# RTC_C__Real_Time_Clock_3 register map
Vendor: Texas Instruments
Peripheral module from a debugger description file (folder msp430).
Registers are 16-bit, read-write, reset 0x0 unless marked. A register's access mark holds for its fields unless they carry their own. Offsets are as the file gives them; lines under a group give offsets from that group; [hi:lo] are bit positions; {n}, {i} and the like mark numbered series; 'fields as' and 'values as' point back to an identical list; <NAME> marks a mode.

## RTC_C_Real_Time_Clock
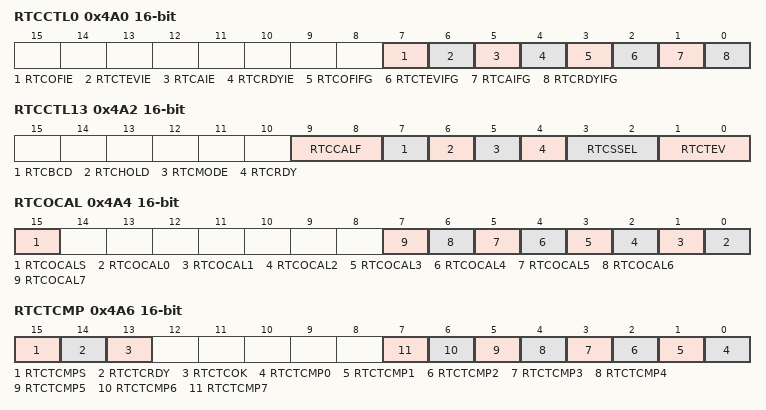
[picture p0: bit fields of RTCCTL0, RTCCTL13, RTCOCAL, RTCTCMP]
0x4A0 RTCCTL0 — Real Timer Clock Control 0/Key
  [7] RTCOFIE — RTC 32kHz cyrstal oscillator fault interrupt enable
  [6] RTCTEVIE — RTC Time Event Interrupt Enable Flag
  [5] RTCAIE — RTC Alarm Interrupt Enable Flag
  [4] RTCRDYIE — RTC Ready Interrupt Enable Flag
  [3] RTCOFIFG — RTC 32kHz cyrstal oscillator fault interrupt flag
  [2] RTCTEVIFG — RTC Time Event Interrupt Flag
  [1] RTCAIFG — RTC Alarm Interrupt Flag
  [0] RTCRDYIFG — RTC Ready Interrupt Flag
0x4A2 RTCCTL13 — Real Timer Clock Control 1/3
  [9:8] RTCCALF — RTC Calibration Frequency Bit 1
    0=RTC Calibration Frequency: No Output; 1=RTC Calibration Frequency: 512 Hz; 2=RTC Calibration Frequency: 256 Hz; 3=RTC Calibration Frequency: 1 Hz
  [7] RTCBCD — RTC BCD 0:Binary / 1:BCD
  [6] RTCHOLD
  [5] RTCMODE — RTC Mode 0:Counter / 1: Calendar
  [4] RTCRDY — RTC Ready
  [3:2] RTCSSEL — RTC Source Select 1
    0=RTC Source Select ACLK; 1=RTC Source Select SMCLK; 2=RTC Source Select RT1PS; 3=RTC Source Select RT1PS
  [1:0] RTCTEV — RTC Time Event 1
    0=RTC Time Event: 0 (Min. changed); 1=RTC Time Event: 1 (Hour changed); 2=RTC Time Event: 2 (12:00 changed); 3=RTC Time Event: 3 (00:00 changed)
0x4A4 RTCOCAL — Real Timer Clock Offset Calibartion
  [15] RTCOCALS — RTC Offset Calibration Sign
  [n] RTCOCAL{n} (n=0..7) — RTC Offset Calibration Bit {n}
0x4A6 RTCTCMP — Real Timer Temperature Compensation
  [15] RTCTCMPS — RTC Temperature Compensation Sign
  [14] RTCTCRDY — RTC Temperature compensation ready
  [13] RTCTCOK — RTC Temperature compensation write OK
  [n] RTCTCMP{n} (n=0..7) — RTC Temperature Compensation Bit {n}
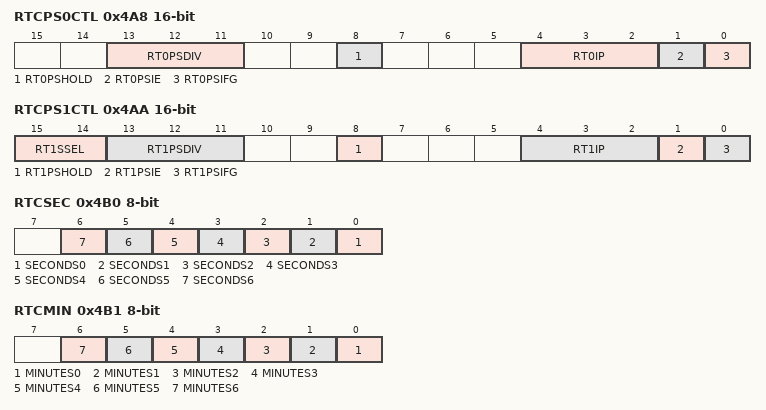
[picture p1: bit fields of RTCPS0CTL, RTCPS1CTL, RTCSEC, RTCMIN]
0x4A8 RTCPS0CTL — Real Timer Prescale Timer 0 Control
  [13:11] RT0PSDIV — RTC Prescale Timer 0 Clock Divide Bit: 2
    0=RTC Prescale Timer 0 Clock Divide: /2; 1=RTC Prescale Timer 0 Clock Divide: /4; 2=RTC Prescale Timer 0 Clock Divide: /8; 3=RTC Prescale Timer 0 Clock Divide: /16; 4=RTC Prescale Timer 0 Clock Divide: /32; 5=RTC Prescale Timer 0 Clock Divide: /64; 6=RTC Prescale Timer 0 Clock Divide: /128; 7=RTC Prescale Timer 0 Clock Divide: /256
  [8] RT0PSHOLD — RTC Prescale Timer 0 Hold
  [4:2] RT0IP — RTC Prescale Timer 0 Interrupt Interval Bit: 2
    0=RTC Prescale Timer 0 Interrupt Interval /2; 1=RTC Prescale Timer 0 Interrupt Interval /4; 2=RTC Prescale Timer 0 Interrupt Interval /8; 3=RTC Prescale Timer 0 Interrupt Interval /16; 4=RTC Prescale Timer 0 Interrupt Interval /32; 5=RTC Prescale Timer 0 Interrupt Interval /64; 6=RTC Prescale Timer 0 Interrupt Interval /128; 7=RTC Prescale Timer 0 Interrupt Interval /256
  [1] RT0PSIE — RTC Prescale Timer 0 Interrupt Enable Flag
  [0] RT0PSIFG — RTC Prescale Timer 0 Interrupt Flag
0x4AA RTCPS1CTL — Real Timer Prescale Timer 1 Control
  [15:14] RT1SSEL — RTC Prescale Timer 1 Source Select Bit: 1
    {v}=RTC Prescale Timer 1 Source Select: {v} (v=0..3)
  [13:11] RT1PSDIV — RTC Prescale Timer 1 Clock Divide Bit: 2
    0=RTC Prescale Timer 1 Clock Divide: /2; 1=RTC Prescale Timer 1 Clock Divide: /4; 2=RTC Prescale Timer 1 Clock Divide: /8; 3=RTC Prescale Timer 1 Clock Divide: /16; 4=RTC Prescale Timer 1 Clock Divide: /32; 5=RTC Prescale Timer 1 Clock Divide: /64; 6=RTC Prescale Timer 1 Clock Divide: /128; 7=RTC Prescale Timer 1 Clock Divide: /256
  [8] RT1PSHOLD — RTC Prescale Timer 1 Hold
  [4:2] RT1IP — RTC Prescale Timer 1 Interrupt Interval Bit: 2
    0=RTC Prescale Timer 1 Interrupt Interval /2; 1=RTC Prescale Timer 1 Interrupt Interval /4; 2=RTC Prescale Timer 1 Interrupt Interval /8; 3=RTC Prescale Timer 1 Interrupt Interval /16; 4=RTC Prescale Timer 1 Interrupt Interval /32; 5=RTC Prescale Timer 1 Interrupt Interval /64; 6=RTC Prescale Timer 1 Interrupt Interval /128; 7=RTC Prescale Timer 1 Interrupt Interval /256
  [1] RT1PSIE — RTC Prescale Timer 1 Interrupt Enable Flag
  [0] RT1PSIFG — RTC Prescale Timer 1 Interrupt Flag
0x4AC RTCPS access not given reset not defined — Real Timer Prescale Timer Control
0x4AE RTCIV access not given reset not defined — Real Time Clock Interrupt Vector
0x4B0 RTCTIM0 access not given reset not defined — Real Time Clock Time 0
0x4B0 RTCSEC 8-bit — Real Time Clock Seconds
  [n] SECONDS{n} (n=0..6) — Real Time Clock Seconds Bit: {n}
0x4B1 RTCMIN 8-bit — Real Time Clock Minutes
  [n] MINUTES{n} (n=0..6) — Real Time Clock Minutes Bit: {n}
0x4B2 RTCTIM1 access not given reset not defined — Real Time Clock Time 1
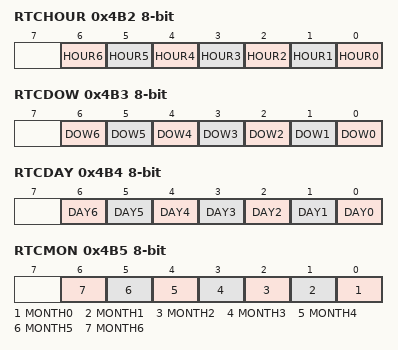
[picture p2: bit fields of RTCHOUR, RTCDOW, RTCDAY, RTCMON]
0x4B2 RTCHOUR 8-bit — Real Time Clock Hour
  [n] HOUR{n} (n=0..6) — Real Time Clock Hour Bit: {n}
0x4B3 RTCDOW 8-bit — Real Time Clock Day of week
  [n] DOW{n} (n=0..6) — Real Time Clock DOW Bit: {n}
0x4B4 RTCDATE access not given reset not defined — Real Time Clock Date
0x4B4 RTCDAY 8-bit — Real Time Clock Day
  [n] DAY{n} (n=0..6) — Real Time Clock Day Bit: {n}
0x4B5 RTCMON 8-bit — Real Time Clock Month
  [n] MONTH{n} (n=0..6) — Real Time Clock Month Bit: {n}
0x4B6 RTCYEAR access not given reset not defined — Real Time Clock Year
0x4B8 RTCAMINHR access not given reset not defined — Real Time Clock Alarm Min/Hour
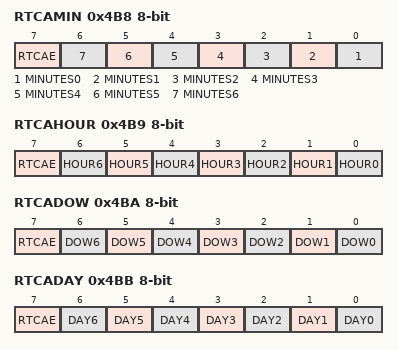
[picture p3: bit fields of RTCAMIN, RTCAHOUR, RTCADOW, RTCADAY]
0x4B8 RTCAMIN 8-bit — Real Time Clock Alarm Min
  [7] RTCAE — Real Time Clock Alarm enable
  [n] MINUTES{n} (n=0..6) — Real Time Clock Minutes Bit: {n}
0x4B9 RTCAHOUR 8-bit — Real Time Clock Alarm Hour
  [7] RTCAE — Real Time Clock Alarm enable
  [n] HOUR{n} (n=0..6) — Real Time Clock Hour Bit: {n}
0x4BA RTCADOWDAY access not given reset not defined — Real Time Clock Alarm day of week/day
0x4BA RTCADOW 8-bit — Real Time Clock Alarm Day of week
  [7] RTCAE — Real Time Clock Alarm enable
  [n] DOW{n} (n=0..6) — Real Time Clock DOW Bit: {n}
0x4BB RTCADAY 8-bit — Real Time Clock Alarm Day
  [7] RTCAE — Real Time Clock Alarm enable
  [n] DAY{n} (n=0..6) — Real Time Clock Day Bit: {n}
0x4BC BIN2BCD access not given reset not defined — Real Time Binary-to-BCD conversion register
0x4BE BCD2BIN access not given reset not defined — Real Time BCD-to-binary conversion register
